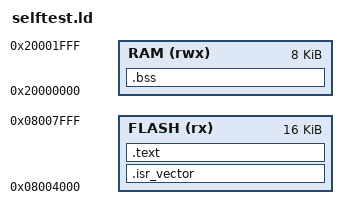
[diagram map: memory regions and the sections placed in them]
/* Self-test image for the emulator core: linked like the application (0x08004000). */
ENTRY(Reset_Handler)
MEMORY
{
    FLASH (rx)  : ORIGIN = 0x08004000, LENGTH = 16K
    RAM   (rwx) : ORIGIN = 0x20000000, LENGTH = 8K
}
_estack = ORIGIN(RAM) + LENGTH(RAM);
SECTIONS
{
    .isr_vector : { KEEP(*(.isr_vector)) } > FLASH
    .text : { *(.text*) *(.rodata*) } > FLASH
    .bss (NOLOAD) : { _sbss = .; *(.bss*) *(COMMON) _ebss = .; } > RAM
}
